# V32F20x_CM33 register map
File version: 1.0.3
CPU: CM33 r0p4, little endian, MPU, FPU, DSP, 3 interrupt priority bits, 8 SAU regions
Registers are 32-bit, read-write, reset 0x0 unless marked. A register's access mark holds for its fields unless they carry their own. Offsets are from the block's base; [hi:lo] are bit positions; {n}, {i} and the like mark numbered series.

## SYSCFG1 — SYSCFG1 Peripheral Interface
Base 0x21030000
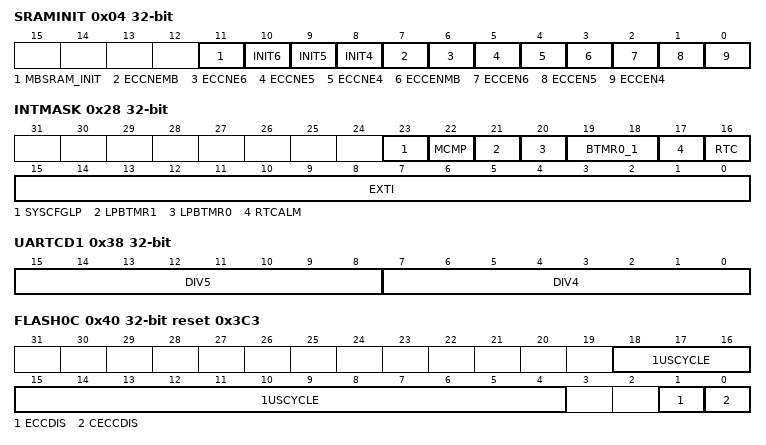
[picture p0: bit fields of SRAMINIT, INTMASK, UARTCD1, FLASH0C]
0x04 SRAMINIT — SRAM initialize and ECC configure register.
  [11] MBSRAM_INIT — Mailbox SRAM initial control initial done signal will clear it automatically
  [10] INIT6 — SRAM6 initial control initial done signal will clear it automatically
  [9] INIT5 — SRAM5 initial control initial done signal will clear it automatically
  [8] INIT4 — SRAM4 initial control initial done signal will clear it automatically
  [7] ECCNEMB — Mailbox SRAM ECC error NMI enable register.
  [6] ECCNE6 — SRAM6 ECC error NMI enable register.
  [5] ECCNE5 — SRAM5 ECC error NMI enable register.
  [4] ECCNE4 — SRAM4 ECC error NMI enable register.
  [3] ECCENMB — Mailbox SRAM ECC check 2 bit error detect enable register
  [2] ECCEN6 — SRAM6 ECC check 2 bit error detect enable register
  [1] ECCEN5 — SRAM5 ECC check 2 bit error detect enable register
  [0] ECCEN4 — SRAM4 ECC check 2 bit error detect enable register
0x08 IREN — UART IrDA enable configure register.
  [5:0] EN — UART14~19 IrDA enable control register
0x0C UARTEN — UART enable configure register.
  [5:0] EN — UART14 19 enable control register
0x10 EGYCFEN — EGY and CF enable configure register.
  [2:0] EN — EGY CF pulse output enable
0x18 PASSWD — Write access protection password register.
  [0] UNLOCK — Write 0xBEEFBEEF to this register to unlock the write access to some password protest register
0x28 INTMASK — CM0 interrupt mask register.
  [23] SYSCFGLP — SYSCFGLP interrupt mask:
  [22] MCMP — MPMU CMP interrupt mask:
  [21] LPBTMR1 — LP basic timer 1 interrupt mask:
  [20] LPBTMR0 — LP basic timer 0 interrupt mask:
  [19:18] BTMR0_1 — Basic timer BTMR0 0/1 interrupt mask:
  [17] RTCALM — RTC alarm interrupt mask:
  [16] RTC — RTC interrupt mask:
  [15:0] EXTI — GPIO EXTI 0 to 15 interrupt mask:
0x38 UARTCD1 — UART clock divider register 1.
  [15:8] DIV5 — Could divide the interface clock for UART19 based on the selected source clock
  [7:0] DIV4 — Could divide the interface clock for UART18 based on the selected source clock
0x40 FLASH0C reset 0x3C3 — Flash 0 control register.
  [18:4] 1USCYCLE — This register is used for flash0 controller to calculate 1us tick from AHB1 clock
  [1] ECCDIS — Flash0 ECC check disable control:
  [0] CECCDIS — Flash0 Cache ECC check disable control:
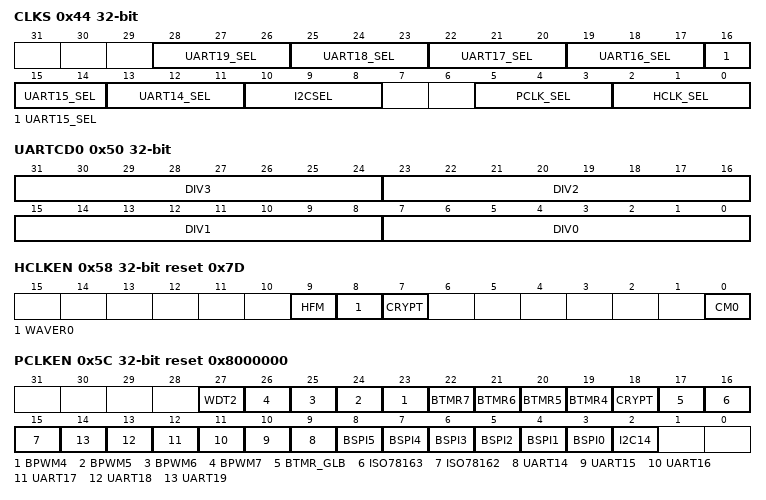
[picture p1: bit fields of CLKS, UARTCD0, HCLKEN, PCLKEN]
0x44 CLKS — Clock selection register.
  [3n-29:3n-31] UART{n}_SEL (n=14..19) — This register is used to control UART{n} interface clock source
  [10:8] I2CSEL — This register is used to control I2C14 interface clock source
  [5:3] PCLK_SEL — This register is used to control APB clock source
  [2:0] HCLK_SEL — This register is used to control AHB clock source.
0x48 HCLKD — AHB clock divider control register.
  [7:0] DIV — This register is used to control AHB clock divider
0x4C PCLKD — APB clock divider control register.
  [7:0] DIV — This register is used to control APB clock divider
0x50 UARTCD0 — UART clock divider register 0.
  [8n+7:8n] DIV{n} (n=0..3) — Could divide the interface clock for UART{n+14} based on the selected source clock
0x58 HCLKEN reset 0x7D — AHB bus peripheral clock enable control register.
  [9] HFM — HFM HCLK enable:
  [8] WAVER0 — WAVER0 HCLK enable:
  [7] CRYPT — CRYPT HCLK enable:
  [0] CM0 — CM0 HCLK enable:
0x5C PCLKEN reset 0x8000000 — APB bus peripheral clock enable control register.
  [27] WDT2 — WDT2 PCLK and function clock enable
  [n+19] BPWM{n} (n=4..7) — Basic PWM timer {n} BPWM{n} clock and function clock enable
  [n+15] BTMR{n} (n=4..7) — Basic timer {n} BTMR{n} clock and function clock enable
  [18] CRYPT — CRYPT PCLK enable
  [17] BTMR_GLB — Basic timer and basic PWM timer global PCLK enable
  [16] ISO78163 — ISO78163 PCLK enable
  [15] ISO78162 — ISO78162 PCLK enable
  [n-5] UART{n} (n=14..19) — UART{n} PCLK and function clock enable
  [n+3] BSPI{n} (n=0..5) — BSPI{n} PCLK enable:
  [2] I2C14 — I2C14 PCLK and function clock enable:
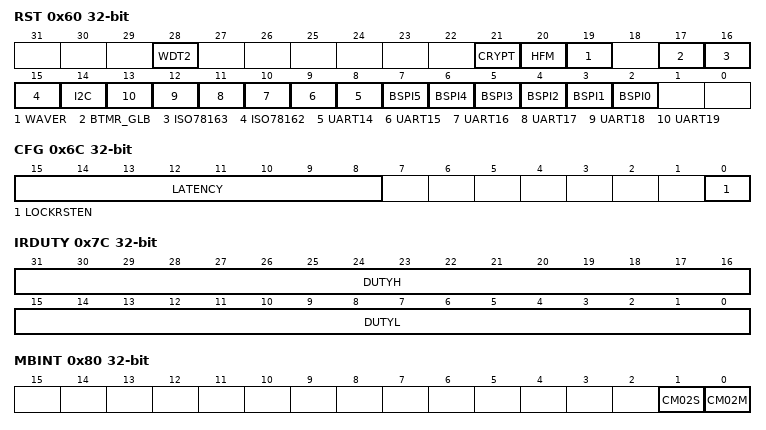
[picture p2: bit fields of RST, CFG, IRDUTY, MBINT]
0x60 RST — Peripheral reset control register 0.
  [28] WDT2 — To reset WDT2 programmer should set this bit to 1
  [21] CRYPT — To reset CRYPT programmer should set this bit to 1
  [20] HFM — To reset HFM programmer should set this bit to 1
  [19] WAVER — To reset WAVER programmer should set this bit to 1
  [17] BTMR_GLB — To global reset basic timer 4 7 programmer should set this bit to 1
  [16] ISO78163 — To reset ISO78163 programmer should set this bit to 1
  [15] ISO78162 — To reset ISO78162 programmer should set this bit to 1
  [14] I2C — To reset I2C programmer should set this bit to 1
  [n-6] UART{n} (n=14..19) — To reset UART{n} programmer should set this bit to 1
  [n+2] BSPI{n} (n=0..5) — To reset BSPI{n} programmer should set this bit to 1
0x64 VTORADDR — CM0 VTOR base address register.
  [31:8] ADDR — The CM0 base address of first 256 bytes space could be redirect to any address through configuring this register
0x6C CFG — CM0 configure register.
  [15:8] LATENCY — CM0 IRQ Latency configuration value.
  [0] LOCKRSTEN — If the CM0 is in the architected lock up state as the result of an unrecoverable exception
0x74 I2CCD — I2C clock divider register.
  [7:0] DIV — Could divide the interface clock for I2C based on the selected source clock
0x78 SEC — CM0 security configure register.
  [0] SEC_BYPASS — CM0 control the CM0 subsystem security bypass
0x7C IRDUTY — UART IrDA duty configure register.
  [31:16] DUTYH — IR high pulse width control register
  [15:0] DUTYL — IR low pulse width control register
0x80 MBINT — MAILBOX CM0 to CM33 interrupt set register.
  [1] CM02S — When CM0 will connect with CM33 CORE1 CM0 will write 1 to this bit and interrupt will generate to CM33 CORE1
  [0] CM02M — When CM0 will connect with CM33 CORE0 CM0 will write 1 to this bit and interrupt will generate to CM33 CORE0
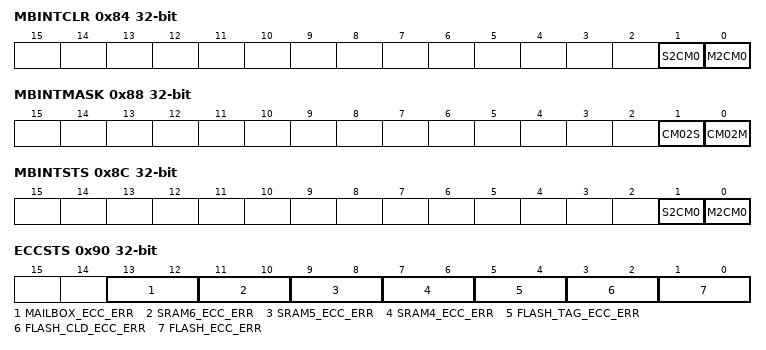
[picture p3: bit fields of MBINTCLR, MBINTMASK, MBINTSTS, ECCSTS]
0x84 MBINTCLR — MAILBOX CM33 to CM0 interrupt clear register.
  [1] S2CM0 — When write 1 to this bit the interrupt CM33 CORE1 to CM0 will be cleared
  [0] M2CM0 — When write 1 to this bit the interrupt CM33 CORE0 to CM0 will be cleared
0x88 MBINTMASK — MAILBOX CM0 to CM33 interrupt mask register.
  [1] CM02S — CM0 to CM33 CORE1 interrupt mask signal
  [0] CM02M — CM0 to CM33 CORE0 interrupt mask signal
0x8C MBINTSTS — MAILBOX CM33 to CM0 interrupt status register.
  [1] S2CM0 — CM33 CORE1 to CM0 mailbox interrupt status
  [0] M2CM0 — CM33 CORE0 to CM0 mailbox interrupt status
0x90 ECCSTS — Memory ECC status register.
  [13:12] MAILBOX_ECC_ERR — Mailbox RAM ECC status
  [11:10] SRAM6_ECC_ERR — SRAM6 ECC status
  [9:8] SRAM5_ECC_ERR — SRAM5 ECC status
  [7:6] SRAM4_ECC_ERR — SRAM4 ECC status
  [5:4] FLASH_TAG_ECC_ERR — Flash0 tag ECC status
  [3:2] FLASH_CLD_ECC_ERR — Flash0 cld ECC status
  [1:0] FLASH_ECC_ERR — Flash0 ECC status
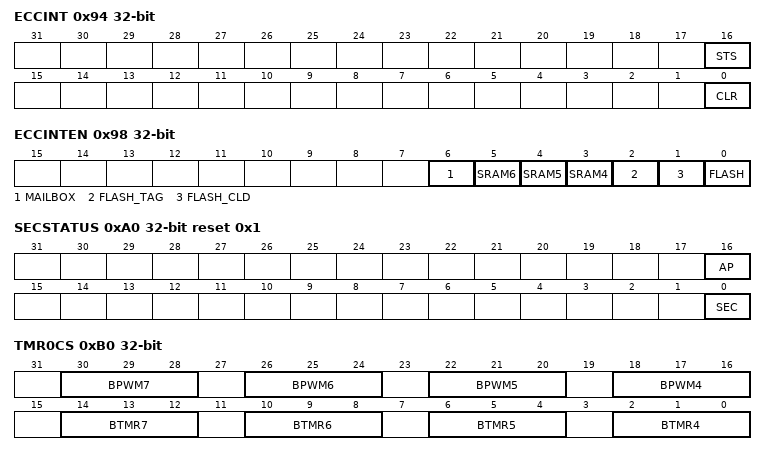
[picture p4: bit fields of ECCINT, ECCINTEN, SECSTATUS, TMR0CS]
0x94 ECCINT — Memory ECC error interrupt stattus and clear register
  [16] STS — Memory ECC error interrupt status
  [0] CLR — Memory ECC error interrupt clear write 1 to clear the interrupt status
0x98 ECCINTEN — Memory ECC interrupt enable register.
  [6] MAILBOX — Mailbox SRAM ECC interrupt enable
  [5] SRAM6 — SRAM6 ECC interrupt enable
  [4] SRAM5 — SRAM5 ECC interrupt enable
  [3] SRAM4 — SRAM4 ECC interrupt enable
  [2] FLASH_TAG — Flash0 tag ECC interrupt enable
  [1] FLASH_CLD — Flash0 cld ECC interrupt enable:
  [0] FLASH — Flash0 ECC interrupt enable:
0xA0 SECSTATUS reset 0x1 — CM0 security status register.
  [16] AP — CM0 AP status
  [0] SEC — CM0 security status
0xB0 TMR0CS — Basic timer and basic PWM timer clock select register
  [4n+2:4n] BPWM{n} (n=4..7) — This register is used to select basic PWM timer {n} BPWM{n} clock source
  [4n-14:4n-16] BTMR{n} (n=4..7) — This register is used to select basic timer {n} BTMR{n} clock source
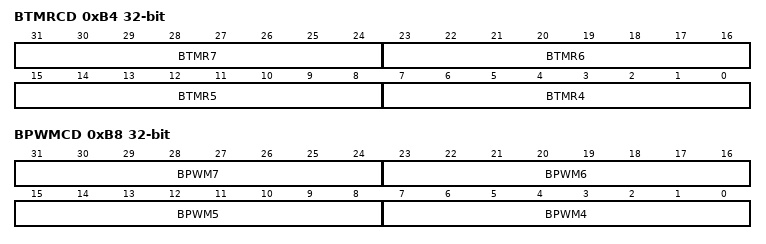
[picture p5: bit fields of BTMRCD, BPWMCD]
0xB4 BTMRCD — Basic timer clock divider configure register.
  [8n-25:8n-32] BTMR{n} (n=4..7) — This register is used to control basic timer {n} BTMR{n} clock divider
0xB8 BPWMCD — Basic PWM timer divider configure register.
  [8n-25:8n-32] BPWM{n} (n=4..7) — This register is used to control basic PWM timer {n} BPWM{n} clock divider
